VERSION ""

NS_ :

BS_:

BU_: Rear_Ultrasonic_Radar_ECU Front_Ultrasonic_Radar_ECU
VAL_TABLE_ Ultrasonic_Information 0 "no obstacle" 254 "sensor error repair" 253 "sensor error temporary" ;

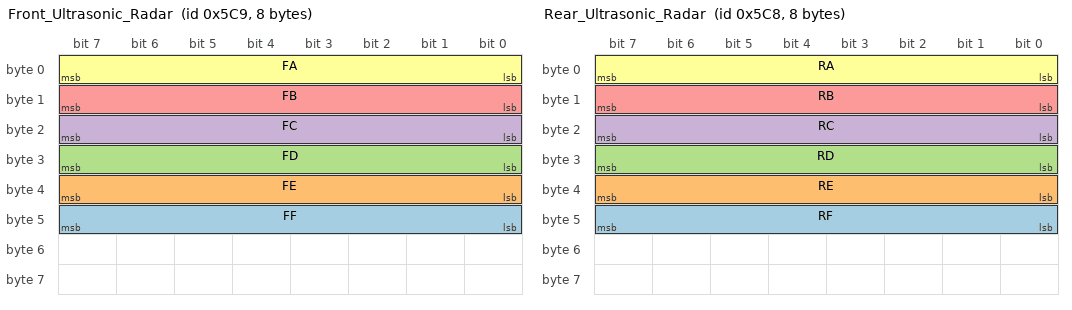
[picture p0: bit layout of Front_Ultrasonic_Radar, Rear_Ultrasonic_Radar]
BO_ 1481 Front_Ultrasonic_Radar: 8 Front_Ultrasonic_Radar_ECU
 SG_ FF : 47|8@0+ (2,0) [0|500] "cm" Vector__XXX
 SG_ FE : 39|8@0+ (2,0) [0|500] "cm" Vector__XXX
 SG_ FD : 31|8@0+ (2,0) [0|500] "cm" Vector__XXX
 SG_ FC : 23|8@0+ (2,0) [0|500] "cm" Vector__XXX
 SG_ FB : 15|8@0+ (2,0) [0|500] "cm" Vector__XXX
 SG_ FA : 7|8@0+ (2,0) [0|500] "cm" Vector__XXX

BO_ 1480 Rear_Ultrasonic_Radar: 8 Rear_Ultrasonic_Radar_ECU
 SG_ RF : 47|8@0+ (2,0) [0|500] "cm" Vector__XXX
 SG_ RE : 39|8@0+ (2,0) [0|500] "cm" Vector__XXX
 SG_ RD : 31|8@0+ (2,0) [0|500] "cm" Vector__XXX
 SG_ RC : 23|8@0+ (2,0) [0|500] "cm" Vector__XXX
 SG_ RB : 15|8@0+ (2,0) [0|500] "cm" Vector__XXX
 SG_ RA : 7|8@0+ (2,0) [0|500] "cm" Vector__XXX

BA_DEF_ SG_  "GenSigSendType" ENUM  "Cyclic","OnWrite","OnWriteWithRepetition","OnChange","OnChangeWithRepetition","IfActive","IfActiveWithRepetition","NoSigSendType";
BA_DEF_ BO_  "GenMsgCycleTime" INT 0 0;
BA_DEF_ BO_  "GenMsgSendType" ENUM  "Cyclic","not_used","not_used","not_used","not_used","Cyclic","not_used","IfActive","NoMsgSendType";
BA_DEF_  "DBName" STRING ;
BA_DEF_  "BusType" STRING ;
BA_DEF_DEF_  "GenSigSendType" "Cyclic";
BA_DEF_DEF_  "GenMsgCycleTime" 0;
BA_DEF_DEF_  "GenMsgSendType" "NoMsgSendType";
BA_DEF_DEF_  "DBName" "";
BA_DEF_DEF_  "BusType" "CAN";
BA_ "DBName" "UDAS";
BA_ "GenMsgCycleTime" BO_ 1481 100;
BA_ "GenMsgSendType" BO_ 1481 0;
BA_ "GenMsgCycleTime" BO_ 1480 100;
BA_ "GenMsgSendType" BO_ 1480 0;
VAL_ 1481 FF 0 "no obstacle" 254 "sensor error repair" 253 "sensor error temporary" ;
VAL_ 1481 FE 0 "no obstacle" 254 "sensor error repair" 253 "sensor error temporary" ;
VAL_ 1481 FD 0 "no obstacle" 254 "sensor error repair" 253 "sensor error temporary" ;
VAL_ 1481 FC 0 "no obstacle" 254 "sensor error repair" 253 "sensor error temporary" ;
VAL_ 1481 FB 0 "no obstacle" 254 "sensor error repair" 253 "sensor error temporary" ;
VAL_ 1481 FA 0 "no obstacle" 254 "sensor error repair" 253 "sensor error temporary" ;
VAL_ 1480 RF 0 "no obstacle" 254 "sensor error repair" 253 "sensor error temporary" ;
VAL_ 1480 RE 0 "no obstacle" 254 "sensor error repair" 253 "sensor error temporary" ;
VAL_ 1480 RD 0 "no obstacle" 254 "sensor error repair" 253 "sensor error temporary" ;
VAL_ 1480 RC 0 "no obstacle" 254 "sensor error repair" 253 "sensor error temporary" ;
VAL_ 1480 RB 0 "no obstacle" 254 "sensor error repair" 253 "sensor error temporary" ;
VAL_ 1480 RA 0 "no obstacle" 254 "sensor error repair" 253 "sensor error temporary" ;
